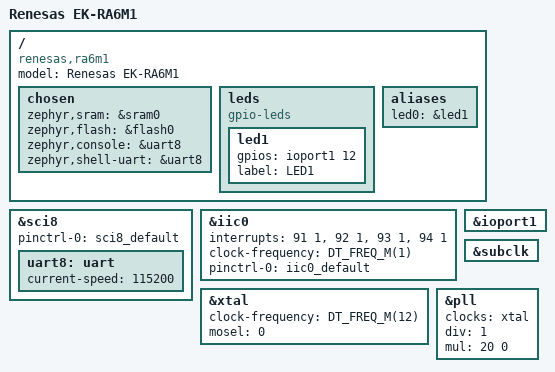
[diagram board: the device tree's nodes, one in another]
/*
 * Copyright (c) 2024 Renesas Electronics Corporation
 * SPDX-License-Identifier: Apache-2.0
 */

/dts-v1/;

#include <renesas/ra/ra6/r7fa6m1ad3cfp.dtsi>
#include <dt-bindings/gpio/gpio.h>

#include "ek_ra6m1-pinctrl.dtsi"

/ {
	model = "Renesas EK-RA6M1";
	compatible = "renesas,ra6m1", "renesas,ra";

	chosen {
		zephyr,sram = &sram0;
		zephyr,flash = &flash0;
		zephyr,console = &uart8;
		zephyr,shell-uart = &uart8;
	};

	leds {
		compatible = "gpio-leds";
		led1: led1 {
			gpios = <&ioport1 12 GPIO_ACTIVE_HIGH>;
			label = "LED1";
		};
	};

	aliases {
		led0 = &led1;
	};
};

&sci8 {
	pinctrl-0 = <&sci8_default>;
	pinctrl-names = "default";
	status = "okay";
	uart8: uart {
		current-speed = <115200>;
		status = "okay";
	};
};

&iic0 {
	status = "okay";
	#address-cells = <1>;
	#size-cells = <0>;
	interrupts = <91 1>, <92 1>, <93 1>, <94 1>;
	interrupt-names = "rxi", "txi", "tei", "eri";
	clock-frequency = <DT_FREQ_M(1)>;
	pinctrl-0 = <&iic0_default>;
	pinctrl-names = "default";
};

&ioport1 {
	status = "okay";
};

&xtal {
	clock-frequency = <DT_FREQ_M(12)>;
	mosel = <0>;
	#clock-cells = <0>;
	status = "okay";
};

&subclk {
	status = "okay";
};

&pll {
	clocks = <&xtal>;
	div = <1>;
	mul = <20 0>;
	status = "okay";
};
